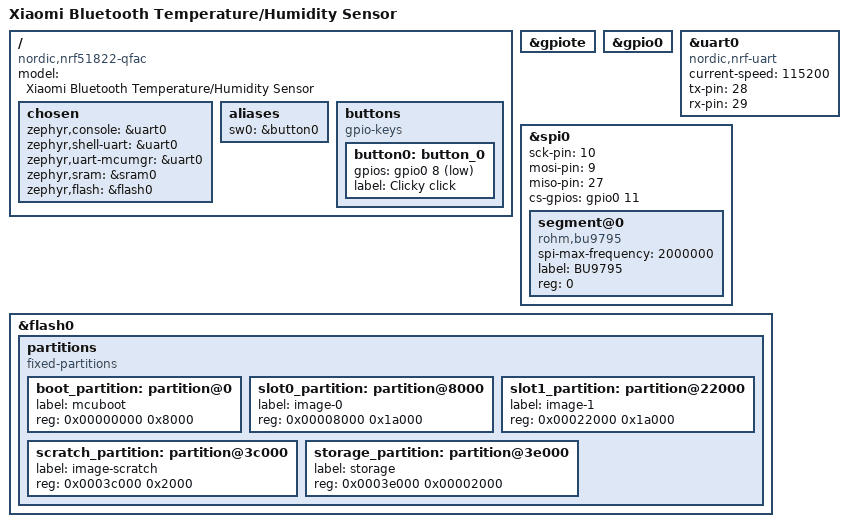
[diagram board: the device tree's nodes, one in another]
/*
 * Copyright (c) 2017 VNG IoT Lab Limited
 *
 * SPDX-License-Identifier: Apache-2.0
 */

/dts-v1/;
#include <nordic/nrf51822_qfac.dtsi>

/ {
	model = "Xiaomi Bluetooth Temperature/Humidity Sensor";
	compatible = "nordic,nrf51822-qfac", "nordic,nrf51822";

	chosen {
		zephyr,console = &uart0;
		zephyr,shell-uart = &uart0;
		zephyr,uart-mcumgr = &uart0;
		zephyr,sram = &sram0;
		zephyr,flash = &flash0;
	};

	/* These aliases are provided for compatibility with samples */
  
	aliases {
		/* led0 = &led0; */
		sw0 = &button0;
  };
  /*
	leds {
		compatible = "gpio-leds";
		led0: led_0 {
			gpios = <&gpio0 7 0>;
			label = "LED";
		};
	};
  */

	buttons {
		/* Push button switch 0 KEY1 */
		compatible = "gpio-keys";
		button0: button_0 {
			/* gpio flags need validation */
			gpios = <&gpio0 8 GPIO_INT_ACTIVE_LOW>;
			label = "Clicky click";
		};
	};
};

&gpiote {
	status ="ok";
};

&gpio0 {
	status ="ok";
};

&uart0 {
	compatible = "nordic,nrf-uart";
	current-speed = <115200>;
	status = "okay";

	tx-pin = <28>;
	rx-pin = <29>;
};

&spi0 {
	status = "okay";
	sck-pin = <10>;
	mosi-pin = <9>;
	// TODO: figure out if a MISO pin has been used
	miso-pin = <27>; // Assign to an unused pin for now
	cs-gpios = <&gpio0 11 0>;

	segment@0 {
		compatible = "rohm,bu9795";
		status = "okay";
		spi-max-frequency = <2000000>;
		label = "BU9795";
		reg = <0>;
	};
};

/*
&i2c0 {
	status = "ok";
	clock-frequency = <I2C_BITRATE_FAST>;
	sda-pin = <29>;
	scl-pin = <30>;
};

*/

&flash0 {
	/*
	 * For more information, see:
	 * http://docs.zephyrproject.org/latest/guides/dts/index.html#flash-partitions
	 */
	partitions {
		compatible = "fixed-partitions";
		#address-cells = <1>;
		#size-cells = <1>;

		boot_partition: partition@0 {
			label = "mcuboot";
			reg = <0x00000000 0x8000>;
		};
		slot0_partition: partition@8000 {
			label = "image-0";
			reg = <0x00008000 0x1a000>;
		};
		slot1_partition: partition@22000 {
			label = "image-1";
			reg = <0x00022000 0x1a000>;
		};
		scratch_partition: partition@3c000 {
			label = "image-scratch";
			reg = <0x0003c000 0x2000>;
		};
		storage_partition: partition@3e000 {
			label = "storage";
			reg = <0x0003e000 0x00002000>;
		};
	};
};
